AUTOSAR XML (schema 4-0-3)
package /ComponentTypes
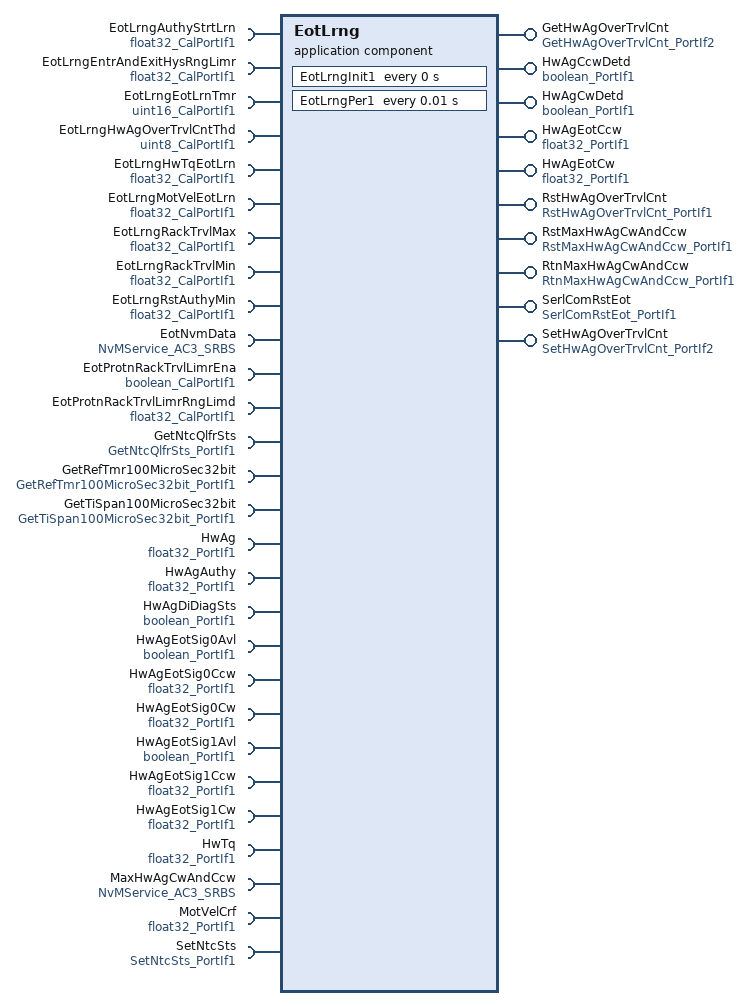
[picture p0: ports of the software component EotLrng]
  application sw component type EotLrng
    10 x provide port:
      GetHwAgOverTrvlCnt: server-com-spec{operation=Oper, queue-length=1}, provided-interface=GetHwAgOverTrvlCnt_PortIf2
      HwAgCcwDetd: nonqueued-sender-com-spec{data-element=Logl, init-value=0}, provided-interface=boolean_PortIf1
      HwAgCwDetd: nonqueued-sender-com-spec{data-element=Logl, init-value=0}, provided-interface=boolean_PortIf1
      HwAgEotCcw: nonqueued-sender-com-spec{data-element=Val, init-value=-360}, provided-interface=float32_PortIf1
      HwAgEotCw: nonqueued-sender-com-spec{data-element=Val, init-value=360}, provided-interface=float32_PortIf1
      RstHwAgOverTrvlCnt: server-com-spec{operation=Oper, queue-length=1}, provided-interface=RstHwAgOverTrvlCnt_PortIf1
      RstMaxHwAgCwAndCcw: server-com-spec{operation=Oper, queue-length=1}, provided-interface=RstMaxHwAgCwAndCcw_PortIf1
      RtnMaxHwAgCwAndCcw: server-com-spec{operation=Oper, queue-length=1}, provided-interface=RtnMaxHwAgCwAndCcw_PortIf1
      SerlComRstEot: server-com-spec{operation=Oper, queue-length=1}, provided-interface=SerlComRstEot_PortIf1
      SetHwAgOverTrvlCnt: server-com-spec{operation=Oper, queue-length=1}, provided-interface=SetHwAgOverTrvlCnt_PortIf2
    28 x require port:
      EotLrngAuthyStrtLrn: parameter-require-com-spec{init-value=1, parameter=Val}, required-interface=float32_CalPortIf1
      EotLrngEntrAndExitHysRngLimr: parameter-require-com-spec{init-value=3, parameter=Val}, required-interface=float32_CalPortIf1
      EotLrngEotLrnTmr: parameter-require-com-spec{init-value=100, parameter=Val}, required-interface=uint16_CalPortIf1
      EotLrngHwAgOverTrvlCntThd: parameter-require-com-spec{init-value=5, parameter=Val}, required-interface=uint8_CalPortIf1
      EotLrngHwTqEotLrn: parameter-require-com-spec{init-value=2, parameter=Val}, required-interface=float32_CalPortIf1
      EotLrngMotVelEotLrn: parameter-require-com-spec{init-value=50, parameter=Val}, required-interface=float32_CalPortIf1
      EotLrngRackTrvlMax: parameter-require-com-spec{init-value=800, parameter=Val}, required-interface=float32_CalPortIf1
      EotLrngRackTrvlMin: parameter-require-com-spec{init-value=400, parameter=Val}, required-interface=float32_CalPortIf1
      EotLrngRstAuthyMin: parameter-require-com-spec{init-value=1, parameter=Val}, required-interface=float32_CalPortIf1
      EotNvmData: required-com-specs=[EraseBlock, GetErrorStatus, InvalidateNvBlock, ReadBlock, SetRamBlockStatus, WriteBlock], required-interface=NvMService_AC3_SRBS
      EotProtnRackTrvlLimrEna: parameter-require-com-spec{init-value=0, parameter=Logl}, required-interface=boolean_CalPortIf1
      EotProtnRackTrvlLimrRngLimd: parameter-require-com-spec{init-value=20, parameter=Val}, required-interface=float32_CalPortIf1
      GetNtcQlfrSts: client-com-spec=Oper, required-interface=GetNtcQlfrSts_PortIf1
      GetRefTmr100MicroSec32bit: client-com-spec=Oper, required-interface=GetRefTmr100MicroSec32bit_PortIf1
      GetTiSpan100MicroSec32bit: client-com-spec=Oper, required-interface=GetTiSpan100MicroSec32bit_PortIf1
      HwAg: nonqueued-receiver-com-spec{data-element=Val, filter=data-filter-type=ALWAYS, init-value=0}, required-interface=float32_PortIf1
      HwAgAuthy: nonqueued-receiver-com-spec{data-element=Val, filter=data-filter-type=ALWAYS, init-value=0}, required-interface=float32_PortIf1
      HwAgDiDiagSts: nonqueued-receiver-com-spec{data-element=Logl, filter=data-filter-type=MASKED-NEW-DIFFERS-MASKED-OLD, init-value=0}, required-interface=boolean_PortIf1
      HwAgEotSig0Avl: nonqueued-receiver-com-spec{data-element=Logl, filter=data-filter-type=ALWAYS, init-value=0}, required-interface=boolean_PortIf1
      HwAgEotSig0Ccw: nonqueued-receiver-com-spec{data-element=Val, filter=data-filter-type=ALWAYS, init-value=0}, required-interface=float32_PortIf1
      HwAgEotSig0Cw: nonqueued-receiver-com-spec{data-element=Val, filter=data-filter-type=ALWAYS, init-value=0}, required-interface=float32_PortIf1
      HwAgEotSig1Avl: nonqueued-receiver-com-spec{data-element=Logl, filter=data-filter-type=ALWAYS, init-value=0}, required-interface=boolean_PortIf1
      HwAgEotSig1Ccw: nonqueued-receiver-com-spec{data-element=Val, filter=data-filter-type=ALWAYS, init-value=0}, required-interface=float32_PortIf1
      HwAgEotSig1Cw: nonqueued-receiver-com-spec{data-element=Val, filter=data-filter-type=ALWAYS, init-value=0}, required-interface=float32_PortIf1
      HwTq: nonqueued-receiver-com-spec{data-element=Val, filter=data-filter-type=ALWAYS, init-value=0}, required-interface=float32_PortIf1
      MaxHwAgCwAndCcw: required-com-specs=[EraseBlock, GetErrorStatus, InvalidateNvBlock, ReadBlock, SetRamBlockStatus, WriteBlock], required-interface=NvMService_AC3_SRBS
      MotVelCrf: nonqueued-receiver-com-spec{data-element=Val, filter=data-filter-type=ALWAYS, init-value=0}, required-interface=float32_PortIf1
      SetNtcSts: client-com-spec=Oper, required-interface=SetNtcSts_PortIf1
    behavior EotLrng_InternalBehavior
      ar-typed-per-instance-memorys:
        9 x data, all with sw-calibration-access=READ-ONLY:
          CcwEotRefTmr: type=uint32
          CwEotRefTmr: type=uint32
          EotNvmData: type=EotNvmDataRec1
          HwAgOverTrvlCntrNegDi: type=boolean
          HwAgOverTrvlCntrPosDi: type=boolean
          MaxHwAgCwAndCcw: type=MaxHwAgCwAndCcwRec2
          PrevCcwEot: type=float32
          PrevCwEot: type=float32
          RstLimReq: type=boolean
      timing event EotLrng_InitEvent: start-on-event=EotLrngInit1, period=0
      timing event TMT_EotLrngPer1: start-on-event=EotLrngPer1, period=0.01
      6 x operation invoked event:
        OIT_GetHwAgOverTrvlCnt_Oper_GetHwAgOverTrvlCnt_Oper: start-on-event=GetHwAgOverTrvlCnt_Oper, operation=GetHwAgOverTrvlCnt.Oper
        OIT_RstHwAgOverTrvlCnt_Oper_RstHwAgOverTrvlCnt_Oper: start-on-event=RstHwAgOverTrvlCnt_Oper, operation=RstHwAgOverTrvlCnt.Oper
        OIT_RstMaxHwAgCwAndCcw_Oper_RstMaxHwAgCwAndCcw_Oper: start-on-event=RstMaxHwAgCwAndCcw_Oper, operation=RstMaxHwAgCwAndCcw.Oper
        OIT_RtnMaxHwAgCwAndCcw_Oper_RtnMaxHwAgCwAndCcw_Oper: start-on-event=RtnMaxHwAgCwAndCcw_Oper, operation=RtnMaxHwAgCwAndCcw.Oper
        OIT_SerlComRstEot_Oper_SerlComRstEot_Oper: start-on-event=SerlComRstEot_Oper, operation=SerlComRstEot.Oper
        OIT_SetHwAgOverTrvlCnt_Oper_SetHwAgOverTrvlCnt_Oper: start-on-event=SetHwAgOverTrvlCnt_Oper, operation=SetHwAgOverTrvlCnt.Oper
      8 x runnable:
        EotLrngInit1
          data-send-points:
            4 x access:
              SEND_HwAgCcwDetd_Logl: accessed-variable=HwAgCcwDetd.Logl
              SEND_HwAgCwDetd_Logl: accessed-variable=HwAgCwDetd.Logl
              SEND_HwAgEotCcw_Val: accessed-variable=HwAgEotCcw.Val
              SEND_HwAgEotCw_Val: accessed-variable=HwAgEotCw.Val
          6 x sync call, all with timeout=0:
            SC_EotNvmData_GetErrorStatus_1: operation=EotNvmData.GetErrorStatus
            SC_EotNvmData_SetRamBlockStatus_1: operation=EotNvmData.SetRamBlockStatus
            SC_GetRefTmr100MicroSec32bit_Oper: operation=GetRefTmr100MicroSec32bit.Oper
            SC_MaxHwAgCwAndCcw_GetErrorStatus: operation=MaxHwAgCwAndCcw.GetErrorStatus
            SC_MaxHwAgCwAndCcw_SetRamBlockStatus: operation=MaxHwAgCwAndCcw.SetRamBlockStatus
            SC_SetNtcSts_Oper: operation=SetNtcSts.Oper
        EotLrngPer1
          data-receive-point-by-arguments:
            11 x access:
              REC_HwAg_Val: accessed-variable=HwAg.Val
              REC_HwAgAuthy_Val: accessed-variable=HwAgAuthy.Val
              REC_HwAgDiDiagSts_Logl: accessed-variable=HwAgDiDiagSts.Logl
              REC_HwAgEotSig0Avl_Logl: accessed-variable=HwAgEotSig0Avl.Logl
              REC_HwAgEotSig0Ccw_Val: accessed-variable=HwAgEotSig0Ccw.Val
              REC_HwAgEotSig0Cw_Val: accessed-variable=HwAgEotSig0Cw.Val
              REC_HwAgEotSig1Avl_Logl: accessed-variable=HwAgEotSig1Avl.Logl
              REC_HwAgEotSig1Ccw_Val: accessed-variable=HwAgEotSig1Ccw.Val
              REC_HwAgEotSig1Cw_Val: accessed-variable=HwAgEotSig1Cw.Val
              REC_HwTq_Val: accessed-variable=HwTq.Val
              REC_MotVelCrf_Val: accessed-variable=MotVelCrf.Val
          data-send-points:
            4 x access:
              SEND_HwAgCcwDetd_Logl: accessed-variable=HwAgCcwDetd.Logl
              SEND_HwAgCwDetd_Logl: accessed-variable=HwAgCwDetd.Logl
              SEND_HwAgEotCcw_Val: accessed-variable=HwAgEotCcw.Val
              SEND_HwAgEotCw_Val: accessed-variable=HwAgEotCw.Val
          7 x sync call, all with timeout=0:
            SC_EotNvmData_GetErrorStatus_1: operation=EotNvmData.GetErrorStatus
            SC_EotNvmData_SetRamBlockStatus_1: operation=EotNvmData.SetRamBlockStatus
            SC_GetNtcQlfrSts_Oper: operation=GetNtcQlfrSts.Oper
            SC_GetRefTmr100MicroSec32bit_Oper: operation=GetRefTmr100MicroSec32bit.Oper
            SC_GetTiSpan100MicroSec32bit_Oper: operation=GetTiSpan100MicroSec32bit.Oper
            SC_MaxHwAgCwAndCcw_SetRamBlockStatus: operation=MaxHwAgCwAndCcw.SetRamBlockStatus
            SC_SetNtcSts_Oper: operation=SetNtcSts.Oper
        GetHwAgOverTrvlCnt_Oper
        RstHwAgOverTrvlCnt_Oper
          sync call SC_MaxHwAgCwAndCcw_SetRamBlockStatus: operation=MaxHwAgCwAndCcw.SetRamBlockStatus, timeout=0
        RstMaxHwAgCwAndCcw_Oper
          sync call SC_MaxHwAgCwAndCcw_SetRamBlockStatus: operation=MaxHwAgCwAndCcw.SetRamBlockStatus, timeout=0
        RtnMaxHwAgCwAndCcw_Oper
        SerlComRstEot_Oper
        SetHwAgOverTrvlCnt_Oper
          sync call SC_MaxHwAgCwAndCcw_SetRamBlockStatus: operation=MaxHwAgCwAndCcw.SetRamBlockStatus, timeout=0
      swc service dependency NvmEotNvmData: assigned-datas=role-based-data-assignment={role=ramBlock, used-data-element=EotNvmData}, assigned-ports=role-based-port-assignment={port-prototype=EotNvmData, role=NvMService_AC3_SRBS}
        service-needs:
          nv block needs NvmEotNvmData: n-data-sets=0, readonly=false, reliability=ERROR-DETECTION, resistant-to-changed-sw=true, restore-at-start=true, store-at-shutdown=true, write-only-once=false, writing-frequency=0, writing-priority=LOW
      swc service dependency NvmMaxHwAgCwAndCcw: assigned-datas=role-based-data-assignment={role=ramBlock, used-data-element=MaxHwAgCwAndCcw}, assigned-ports=role-based-port-assignment={port-prototype=MaxHwAgCwAndCcw, role=NvMService_AC3_SRBS}
        service-needs:
          nv block needs NvmMaxHwAgCwAndCcw: n-data-sets=0, readonly=false, reliability=ERROR-DETECTION, resistant-to-changed-sw=true, restore-at-start=true, store-at-shutdown=true, write-only-once=false, writing-frequency=0, writing-priority=LOW
      shared-parameters:
        parameter data prototype EotNvmDataDft: sw-calibration-access=READ-WRITE, type=EotNvmDataRec1
  swc implementation EotLrng_Implementation: behavior=EotLrng_InternalBehavior
    code-descriptors:
      code Default: artifact-descriptors=autosar-engineering-object={short-label=Default, category=SWSRC}
